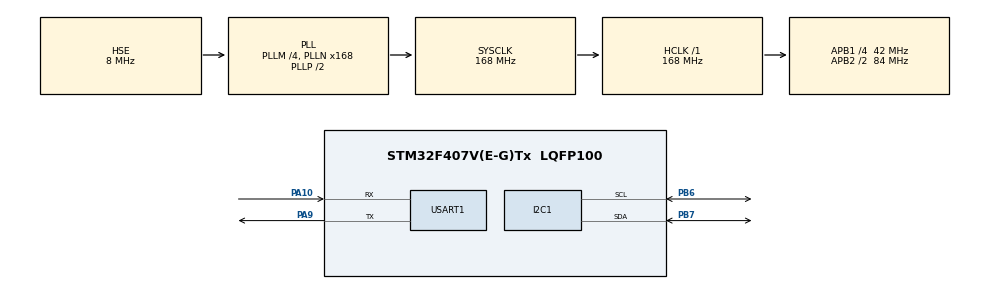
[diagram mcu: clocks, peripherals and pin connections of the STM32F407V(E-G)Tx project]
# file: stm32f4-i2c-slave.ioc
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Dma.I2C1_RX.0.Direction=DMA_PERIPH_TO_MEMORY
Dma.I2C1_RX.0.FIFOMode=DMA_FIFOMODE_DISABLE
Dma.I2C1_RX.0.Instance=DMA1_Stream0
Dma.I2C1_RX.0.MemDataAlignment=DMA_MDATAALIGN_BYTE
Dma.I2C1_RX.0.MemInc=DMA_MINC_ENABLE
Dma.I2C1_RX.0.Mode=DMA_NORMAL
Dma.I2C1_RX.0.PeriphDataAlignment=DMA_PDATAALIGN_BYTE
Dma.I2C1_RX.0.PeriphInc=DMA_PINC_DISABLE
Dma.I2C1_RX.0.Priority=DMA_PRIORITY_HIGH
Dma.I2C1_TX.1.Direction=DMA_MEMORY_TO_PERIPH
Dma.I2C1_TX.1.FIFOMode=DMA_FIFOMODE_DISABLE
Dma.I2C1_TX.1.Instance=DMA1_Stream6
Dma.I2C1_TX.1.MemDataAlignment=DMA_MDATAALIGN_BYTE
Dma.I2C1_TX.1.MemInc=DMA_MINC_ENABLE
Dma.I2C1_TX.1.Mode=DMA_NORMAL
Dma.I2C1_TX.1.PeriphDataAlignment=DMA_PDATAALIGN_BYTE
Dma.I2C1_TX.1.PeriphInc=DMA_PINC_DISABLE
Dma.I2C1_TX.1.Priority=DMA_PRIORITY_HIGH
Dma.Request0=I2C1_RX
Dma.Request1=I2C1_TX
I2C1.GeneralCallMode=I2C_GENERALCALL_DISABLE
Mcu.Family=STM32F4
Mcu.Name=STM32F407V(E-G)Tx
Mcu.Package=LQFP100
NVIC.DMA1_Stream0_IRQn=true\:0\:0\:false\:false\:true\:false\:true
NVIC.DMA1_Stream6_IRQn=true\:0\:0\:false\:false\:true\:false\:true
NVIC.I2C1_ER_IRQn=true\:0\:0\:false\:false\:true\:true\:true
NVIC.I2C1_EV_IRQn=true\:0\:0\:false\:false\:true\:true\:true
NVIC.PriorityGroup=NVIC_PRIORITYGROUP_4
PA10.Mode=Asynchronous
PA10.Signal=USART1_RX
PA13.Mode=Serial_Wire
PA13.Signal=SYS_JTMS-SWDIO
PA14.Mode=Serial_Wire
PA14.Signal=SYS_JTCK-SWCLK
PA9.Mode=Asynchronous
PA9.Signal=USART1_TX
PB6.Mode=I2C
PB6.Signal=I2C1_SCL
PB7.Mode=I2C
PB7.Signal=I2C1_SDA
PH0-OSC_IN.Mode=HSE-External-Oscillator
PH0-OSC_IN.Signal=RCC_OSC_IN
PH1-OSC_OUT.Mode=HSE-External-Oscillator
PH1-OSC_OUT.Signal=RCC_OSC_OUT
ProjectManager.HeapSize=0x200
ProjectManager.StackSize=0x400
ProjectManager.TargetToolchain=STM32CubeIDE
RCC.48MHZClocksFreq_Value=84000000
RCC.AHBFreq_Value=168000000
RCC.APB1CLKDivider=RCC_HCLK_DIV4
RCC.APB1Freq_Value=42000000
RCC.APB1TimFreq_Value=84000000
RCC.APB2CLKDivider=RCC_HCLK_DIV2
RCC.APB2Freq_Value=84000000
RCC.APB2TimFreq_Value=168000000
RCC.CortexFreq_Value=168000000
RCC.HCLKFreq_Value=168000000
RCC.HSE_VALUE=8000000
RCC.HSI_VALUE=16000000
RCC.LSE_VALUE=32768
RCC.PLLM=4
RCC.PLLN=168
RCC.PLLSourceVirtual=RCC_PLLSOURCE_HSE
RCC.SYSCLKFreq_VALUE=168000000
RCC.SYSCLKSource=RCC_SYSCLKSOURCE_PLLCLK
RCC.VCOOutputFreq_Value=336000000
USART1.VirtualMode=VM_ASYNC
board=custom

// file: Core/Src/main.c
/* USER CODE BEGIN Header */
/**
  ******************************************************************************
  * @file           : main.c
  * @brief          : Main program body
  ******************************************************************************
  * @attention
  *
  * <h2><center>&copy; Copyright (c) 2020 STMicroelectronics.
  * All rights reserved.</center></h2>
  *
  * This software component is licensed by ST under BSD 3-Clause license,
  * the "License"; You may not use this file except in compliance with the
  * License. You may obtain a copy of the License at:
  *                        opensource.org/licenses/BSD-3-Clause
  *
  ******************************************************************************
  */
/* USER CODE END Header */

#include "main.h"

I2C_HandleTypeDef hi2c1;
DMA_HandleTypeDef hdma_i2c1_rx;
DMA_HandleTypeDef hdma_i2c1_tx;

UART_HandleTypeDef huart1;

void SystemClock_Config(void);
static void MX_GPIO_Init(void);
static void MX_DMA_Init(void);
static void MX_I2C1_Init(void);
static void MX_USART1_UART_Init(void);

/* USER CODE BEGIN 0 */
int app_main(void);
/* USER CODE END 0 */

int main(void)
{

  /* MCU Configuration--------------------------------------------------------*/

  /* Reset of all peripherals, Initializes the Flash interface and the Systick. */
  HAL_Init();

  /* Configure the system clock */
  SystemClock_Config();

  /* Initialize all configured peripherals */
  MX_GPIO_Init();
  MX_DMA_Init();
  MX_I2C1_Init();
  MX_USART1_UART_Init();
  /* USER CODE BEGIN 2 */
  int app_main(void);
  /* USER CODE END 2 */

  /* Infinite loop */

}

void SystemClock_Config(void)
{
  RCC_OscInitTypeDef RCC_OscInitStruct = {0};
  RCC_ClkInitTypeDef RCC_ClkInitStruct = {0};

  /** Configure the main internal regulator output voltage
  */
  __HAL_RCC_PWR_CLK_ENABLE();
  __HAL_PWR_VOLTAGESCALING_CONFIG(PWR_REGULATOR_VOLTAGE_SCALE1);
  /** Initializes the CPU, AHB and APB busses clocks
  */
  RCC_OscInitStruct.OscillatorType = RCC_OSCILLATORTYPE_HSE;
  RCC_OscInitStruct.HSEState = RCC_HSE_ON;
  RCC_OscInitStruct.PLL.PLLState = RCC_PLL_ON;
  RCC_OscInitStruct.PLL.PLLSource = RCC_PLLSOURCE_HSE;
  RCC_OscInitStruct.PLL.PLLM = 4;
  RCC_OscInitStruct.PLL.PLLN = 168;
  RCC_OscInitStruct.PLL.PLLP = RCC_PLLP_DIV2;
  RCC_OscInitStruct.PLL.PLLQ = 4;
  if (HAL_RCC_OscConfig(&RCC_OscInitStruct) != HAL_OK)
  {
    Error_Handler();
  }
  /** Initializes the CPU, AHB and APB busses clocks
  */
  RCC_ClkInitStruct.ClockType = RCC_CLOCKTYPE_HCLK|RCC_CLOCKTYPE_SYSCLK
                              |RCC_CLOCKTYPE_PCLK1|RCC_CLOCKTYPE_PCLK2;
  RCC_ClkInitStruct.SYSCLKSource = RCC_SYSCLKSOURCE_PLLCLK;
  RCC_ClkInitStruct.AHBCLKDivider = RCC_SYSCLK_DIV1;
  RCC_ClkInitStruct.APB1CLKDivider = RCC_HCLK_DIV4;
  RCC_ClkInitStruct.APB2CLKDivider = RCC_HCLK_DIV2;

  if (HAL_RCC_ClockConfig(&RCC_ClkInitStruct, FLASH_LATENCY_5) != HAL_OK)
  {
    Error_Handler();
  }
}

static void MX_I2C1_Init(void)
{

  hi2c1.Instance = I2C1;
  hi2c1.Init.ClockSpeed = 100000;
  hi2c1.Init.DutyCycle = I2C_DUTYCYCLE_2;
  hi2c1.Init.OwnAddress1 = 0;
  hi2c1.Init.AddressingMode = I2C_ADDRESSINGMODE_7BIT;
  hi2c1.Init.DualAddressMode = I2C_DUALADDRESS_DISABLE;
  hi2c1.Init.OwnAddress2 = 0;
  hi2c1.Init.GeneralCallMode = I2C_GENERALCALL_DISABLE;
  hi2c1.Init.NoStretchMode = I2C_NOSTRETCH_DISABLE;
  if (HAL_I2C_Init(&hi2c1) != HAL_OK)
  {
    Error_Handler();
  }

}

static void MX_USART1_UART_Init(void)
{

  huart1.Instance = USART1;
  huart1.Init.BaudRate = 115200;
  huart1.Init.WordLength = UART_WORDLENGTH_8B;
  huart1.Init.StopBits = UART_STOPBITS_1;
  huart1.Init.Parity = UART_PARITY_NONE;
  huart1.Init.Mode = UART_MODE_TX_RX;
  huart1.Init.HwFlowCtl = UART_HWCONTROL_NONE;
  huart1.Init.OverSampling = UART_OVERSAMPLING_16;
  if (HAL_UART_Init(&huart1) != HAL_OK)
  {
    Error_Handler();
  }

}

static void MX_DMA_Init(void)
{

  /* DMA controller clock enable */
  __HAL_RCC_DMA1_CLK_ENABLE();

  /* DMA interrupt init */
  /* DMA1_Stream0_IRQn interrupt configuration */
  HAL_NVIC_SetPriority(DMA1_Stream0_IRQn, 0, 0);
  HAL_NVIC_EnableIRQ(DMA1_Stream0_IRQn);
  /* DMA1_Stream6_IRQn interrupt configuration */
  HAL_NVIC_SetPriority(DMA1_Stream6_IRQn, 0, 0);
  HAL_NVIC_EnableIRQ(DMA1_Stream6_IRQn);

}

static void MX_GPIO_Init(void)
{

  /* GPIO Ports Clock Enable */
  __HAL_RCC_GPIOH_CLK_ENABLE();
  __HAL_RCC_GPIOA_CLK_ENABLE();
  __HAL_RCC_GPIOB_CLK_ENABLE();

}

void Error_Handler(void)
{
}

/************************ (C) COPYRIGHT STMicroelectronics *****END OF FILE****/
